# PIC32CK1025SG00064 device description
Architecture: CORTEX-M33; Family: PIC32CK; Series: PIC32CKSG00
Registers are 32-bit, read-write, reset 0x0 unless marked. A register's access mark holds for its fields unless they carry their own. Offsets are from the block's base; [hi:lo] are bit positions; lines under a group give offsets from that group; {n}, {i} and the like mark numbered series; 'fields as' and 'values as' point back to an identical list; <NAME> marks a mode.

## USBHS — USB High Speed
Instances: USBHS 0x46000000
Modes: ENDPOINTX when USBHS.INDEX.SELEP=1 (Endpont 1-15 are selected. INDEX.SELEP value needs to be greater than 0); ENDPOINT0 when USBHS.INDEX.SELEP=0 (Endpont 0 is selected)
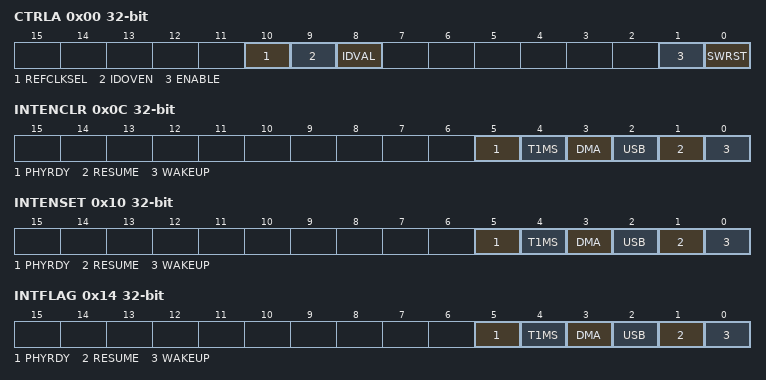
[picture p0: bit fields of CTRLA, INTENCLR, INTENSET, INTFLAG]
0x00 CTRLA — USBHS Control Register A. (All bits except ENABLE and SWRST are Enable protected)
  [10] REFCLKSEL — Select USB PLL Reference Clock Speed
  [9] IDOVEN — ID Source Select
  [8] IDVAL — Override Valud of ID
  [1] ENABLE — USBHS Enable
  [0] SWRST — USBHS Software Reset
0x04 CTRLB — USBHS Control Register B
  [19:0] BLANK — Blank the wakeup monitoring for a specific real time
    0=No blank delay; 0xFFFFF=BLANKMAX (Maximum blank delay)
0x08 CTRLC — USBHS Control Register C
  [4] T1MSEN — REFCLK and SUSPENDM override
0x0C INTENCLR (atomic clear) — USBHS Interrupt Enable Clear Register
  [5] PHYRDY — Clear PHYRDY Interrupt Enable
  [4] T1MS — Clear T1MS Interrupt Enable
  [3] DMA — Clear DMA Interrupt Enable
  [2] USB — Clear USBCORE General Interrupt Enable
  [1] RESUME — Clear Resume Interrupt Enable
  [0] WAKEUP — Clear USCORE Detaction Interrupt Enable
0x10 INTENSET (atomic set) — USBHS Interrupt Enable Clear Register
  [5] PHYRDY — PHYRDY Interrupt Enable
  [4] T1MS — T1MS Interrupt Enable
  [3] DMA — DMA Interrupt Enable
  [2] USB — USBCORE General Interrupt Enable
  [1] RESUME — Resume Interrupt Enable
  [0] WAKEUP — USCORE Detaction Interrupt Enable
0x14 INTFLAG (atomic clear) — USBHS Interrupt Flag Register
  [5] PHYRDY — PHY Ready Interrupt
  [4] T1MS — Timer 1ms Tick Interrupt
  [3] DMA — DMA Interrupt
  [2] USB — USBCORE General Interrupt
  [1] RESUME — Resume Interrupt
  [0] WAKEUP — USB Activity Detection Interrupt
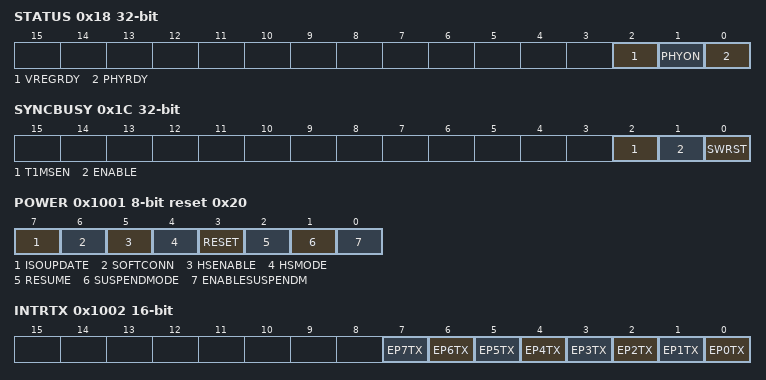
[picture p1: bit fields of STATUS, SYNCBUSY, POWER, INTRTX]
0x18 STATUS ro — USBHS Status Register
  [2] VREGRDY — USB Voltage Regulator Status
  [1] PHYON — Power On of PHY Complete
  [0] PHYRDY — PHY Is Ready for USBCORE Activity
0x1C SYNCBUSY ro — USBHS Syncbusy Register
  [2] T1MSEN — T1MS enable busy bit
  [1] ENABLE — Enable busy bit
  [0] SWRST — Software reset busy bit
0x1000 FADDR 8-bit — Function Address Register
  [6:0] FUNCADDR — Function address
0x1001 POWER 8-bit reset 0x20 — Used For Controlling Suspend And Resume Signaling And Some Basic Operation Of USBCORE
  [7] ISOUPDATE — when set by cpu the usbcore will wait for an sof token
  [6] SOFTCONN — if enabled the D+ D- lines are enabled when this bit is set by the cpu
  [5] HSENABLE — when set by cpu the usbcore will negotiate the high speed mode
  [4] HSMODE — when set this read only bit indicates high speed mode successfully negotiated during usb reset
  [3] RESET — this bit is set when reset signaling is present on the bus
  [2] RESUME — set by cpu to generate resume signaling when te device is in suspend
  [1] SUSPENDMODE — set by cpu to enter suspend mode
  [0] ENABLESUSPENDM — set by the cpu to enable suspendm output
0x1002 INTRTX 16-bit ro (atomic clear) — Read Only Register Which Indicates Which Interrupts Are Currently Active For EP0 And TX EP1-15
  [n] EP{n}TX (n=0..7) — Interrupts Active For TX{n} Endpoint
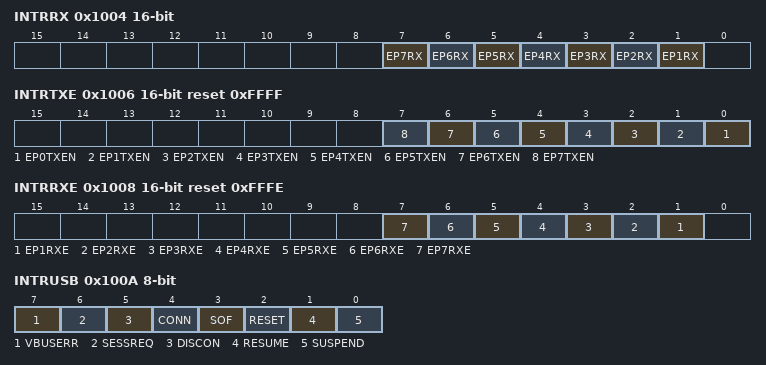
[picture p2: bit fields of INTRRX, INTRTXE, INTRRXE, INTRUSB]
0x1004 INTRRX 16-bit ro (atomic clear) — Read Only Register Which Indicates Which Interrupts Are Currently Active For RX EP1-15
  [n] EP{n}RX (n=1..7) — Interrupts Active For Which RX{n} Endpoint
0x1006 INTRTXE 16-bit reset 0xFFFF — Interrupt Enable Bits for INTRTX
  [n] EP{n}TXEN (n=0..7) — Interrupt Enabled for TX EP{n}
0x1008 INTRRXE 16-bit reset 0xFFFE — Interrupt Enable Bits for INTRRX
  [n] EP{n}RXE (n=1..7) — Interrupt Enabled for RX EP{n}
0x100A INTRUSB 8-bit ro (atomic clear) — Read Only Register Which Indicates Which USB Interrupts Are Currently Active.
  [7] VBUSERR — Set When VBus Drops Below The VBus Valid Threshold During A Session.
  [6] SESSREQ — Set When Session Request Signaling Has Been Detected.
  [5] DISCON — Set In Host Mode When A Device Disconnect Is Detected.Set In Peripheral Mode When A Session Ends
  [4] CONN — Set When A Device Connection Is Detected
  [3] SOF — Set When A New Frame Starts
  [2] RESET — Set In Peripheral Mode when Reset Is Detected On The Bus. In HostMode When Babble Is Detected
  [1] RESUME — Set When Resume Signal Is Detected On The Bus
  [0] SUSPEND — Set When Suspend Signal Is Detected On The Bus
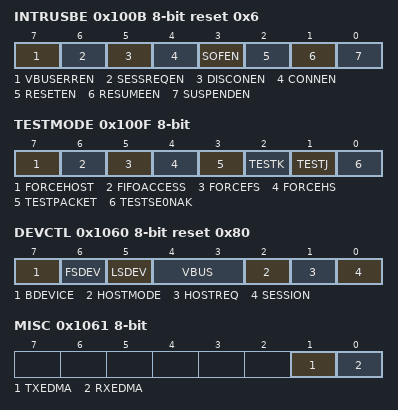
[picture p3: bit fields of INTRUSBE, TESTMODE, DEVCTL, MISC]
0x100B INTRUSBE 8-bit reset 0x6 — Interrupt Enable Bits for USB Interrupts
  [7] VBUSERREN — VBus Error Interrupt Enable
  [6] SESSREQEN — SESSREQ Interrupt Enable
  [5] DISCONEN — DISCONN Interrupt Enable
  [4] CONNEN — CONN Interrupt Enable
  [3] SOFEN — SOF Interrupt Enable
  [2] RESETEN — RESET/BABBLE Interrupt Enable
  [1] RESUMEEN — RESUME Interrupt Enable
  [0] SUSPENDEN — SUSEPND Interrupt Enable
0x100C FRAME 16-bit ro — Holds The Last Received Frame Number
  [10:0] FRMNUM — Frame Number
0x100E INDEX 8-bit — Index Is A 4-Bit Register That Determines Which Endpoint Control/Status Registers Are Accessed
  [3:0] SELEP — The Selected Endpoint
    {v}=EP{v} (Endpoint {v} Select) (v=0..8)
0x100F TESTMODE 8-bit — Not Used In Normal Operation. Configuration To Put the USBCORE Into One Of The Four Test Modes For HighSpeed Operation
  [7] FORCEHOST — The CPU Sets This Bit To Instruct The Core To Enter Host Mode When The Session Bit Is Set
  [6] FIFOACCESS — The CPU Sets This Bit To Transfer The Packet In The Endpoint 0 TX FIFO To The Endpoint 0 Rx FIFO. It Is Cleared Automatically.
  [5] FORCEFS — Depending On Bit 7 Force Controller Into FS Speed Mode
  [4] FORCEHS — Depending On Bit 7 Force Controller Into High Speed Mode
  [3] TESTPACKET — Set To Enter The Test_Packet mode
  [2] TESTK — Set To Enter The Test_K mode
  [1] TESTJ — Set To Enter The Test_J mode
  [0] TESTSE0NAK — Set To Enter The Test_SE0_NAK mode
{0x1020+4i} FIFOX[{i}] (i=0..7) — Address Range Provides 16 Addresses For CPU Access To The FIFO's For Each Endpoint
  [31:0] FIFOADDR — Writing To These Addresses Loads Data Into The TXFIFO For The Corresponding Endpoint
0x1060 DEVCTL 8-bit reset 0x80 — Selects Whether The Core Is Operating In Peripheral Or Host Mode
  [7] BDEVICE — indicates whether the core is operating as a 'A' device or 'B' device
  [6] FSDEV — host mode only: this bit is set when a full or high speed device has been detected being connected to the port
  [5] LSDEV — host mode only: this bit is set when a low speed device has been detected being connected to the port
  [4:3] VBUS — encoded value for the VBus level
    0=BSESSEND (Below SessionEnd); 1=ASESSEND (Above SessionEnd, below AValid); 2=AAVALID (Above AValid, below VBus Valid); 3=AVBUSVALID (Above VBusValid)
  [2] HOSTMODE — this read-only bit is set when the USBCORE is acting as a host
  [1] HOSTREQ — when set, the USBCORE will initiate the host negotiation when suspend mode is entered.
  [0] SESSION — when operating as an 'A' device, this bit is set or cleared by CPU to state or end a session. when operating as a 'B' device, this bit is set/cleared by the USBCORE when a session starts/ends
0x1061 MISC 8-bit — RX/TX Early DMA Enable Bits
  [1] TXEDMA — DMA_REQ signal for all IN endpoints will be deasserted based on this bit selection
    0=MAXP (Dma_req signal for all in endpoints will be de-asserted when maxp bytes have been written to an endpoint. this is late mode.); 1=MAXP_8 (Dma_req signal for all in endpoints will be de-asserted when maxp-8 bytes have been written to an endpoint. this is early mode.)
  [0] RXEDMA — DMA_REQ signal for all OUT endpoints will be deasserted based on this bit selection
    0=MAXP (Dma_req signal for all out endpoints will be de-asserted when maxp bytes have been written to an endpoint. this is late mode.); 1=MAXP_8 (Dma_req signal for all out endpoints will be de-asserted when maxp-8 bytes have been written to an endpoint. this is early mode.)
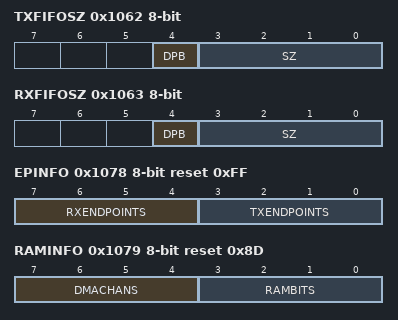
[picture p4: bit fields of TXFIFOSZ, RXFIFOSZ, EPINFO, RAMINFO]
0x1062 TXFIFOSZ 8-bit — Controls The Size Of The Selected TX Endpoint FIFO
  [4] DPB — double packet buffering supported or not
  [3:0] SZ — maximum packet size to be allowed
    0=8BYTES; 1=16BYTES; 2=32BYTES; 3=64BYTES; 4=128BYTES; 5=256BYTES; 6=512BYTES; 7=1024BYTES; 8=2048BYTES; 9=4096BYTES
0x1063 RXFIFOSZ 8-bit — Controls The Size Of The Selected RX Endpoint FIFO
  [4] DPB — double packet buffering enabled or not
  [3:0] SZ — maximum packet size to be allowed
    values as TXFIFOSZ.SZ
0x1064 TXFIFOADD 16-bit — Controls The Start Address Of the Selected TX Endpoint FIFO
  [12:0] ADDR — start address of the endpoint FIFO
0x1066 RXFIFOADD 16-bit — Controls The Start Address Of the Selected RX Endpoint FIFO
  [12:0] ADDR — start address of the endpoint FIFO
0x1078 EPINFO 8-bit ro reset 0xFF — Allows Read-Back Of The Number Of TX And RX Endpoints
  [7:4] RXENDPOINTS — number of rx endpoints
  [3:0] TXENDPOINTS — number of tx endpoints
0x1079 RAMINFO 8-bit ro reset 0x8D — Details About Width Of RAM and DMA Channels
  [7:4] DMACHANS — number of dma channels implemented in the design
  [3:0] RAMBITS — width of the ram address bus
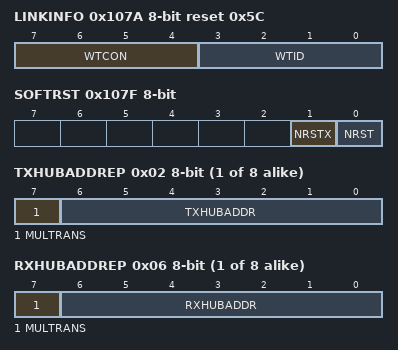
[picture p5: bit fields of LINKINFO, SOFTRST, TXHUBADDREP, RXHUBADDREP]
0x107A LINKINFO 8-bit reset 0x5C — Allows Some Delays To Be Specified
  [7:4] WTCON — sets the wait to be applied to allow for the user's connect/disconnect filter in units of 533.3ns
  [3:0] WTID — sets the delay to be applied from idpullup being asserted to iddig being considered valid in units of 4.369ms
0x107B VPLEN 8-bit reset 0x3C — Sets The Duration Of The VBus Pulsing Charge
  [7:0] VPLEN — duration of VBus pulsing charge in units of 546.1us
0x107C HSEOF1 8-bit reset 0x80 — Sets The Minimum Time Gap That Is To Be Allowed Between The Start Of The Last Transaction And The EOF For HS Transactions
  [7:0] HSEOF1 — sets for high-speed transactions the time before eof to stop beginning new transactions, in units of 133.3ns. (the default setting corresponds to 17.07us.)
0x107D FSEOF1 8-bit reset 0x77 — Sets The Minimum Time Gap That Is To Be Allowed Between The Start Of The Last Transaction And The EOF For FS Transactions
  [7:0] FSEOF1 — sets for full-speed transactions the time before eof to stop beginning new transactions, in units of 533.3ns. (the default setting corresponds to 63.46us.)
0x107E LSEOF1 8-bit reset 0x72 — Sets The Minimum Time Gap That Is To Be Allowed Between The Start Of The Last Transaction And The EOF For LS Transactions
  [7:0] LSEOF1 — sets for low-speed transactions the time before eof to stop beginning new transactions, in units of 1.067us. (the default setting corresponds to 121.6us.)
0x107F SOFTRST 8-bit — Assert Low The Output Reset Signals NRSTO and NRSTXO
  [1] NRSTX — when a 1 is written to this bit, the output nrstxo will be asserted (low) within a minimum delay of 7 cycles of the clk input. the output nrstxo will be asynchronously asserted and synchronously de-asserted with respect to xclk.
  [0] NRST — when a 1 is written to this bit, the output nrsto will be asserted (low) within a minimum delay of 7 cycles of the clk input. the output nrsto will be asynchronously asserted and synchronously de-asserted with respect to clk.
{0x1080+8i} TXFUNADDR[{i}] (i=0..7) group
  0x00 TXFUNCADDREP 8-bit — Relevant In Host Mode Only. Address Of The Target Function.
    [6:0] TXFUNCADDR — address of the target function
  0x02 TXHUBADDREP 8-bit — Relevant In Host Mode Only. HUB Address
    [7] MULTRANS — hub has multiple or single translator
    [6:0] TXHUBADDR — hub address
  0x03 TXHUBPORT 8-bit — Relevant In Host Mode Only. HUB Address
    [6:0] HUBPORT
  0x04 RXFUNCADDREP 8-bit — Relevant In Host Mode Only. Address Of The Target Function.
    [6:0] RXFUNCADDR — address of the target function
  0x06 RXHUBADDREP 8-bit — Relevant In Host Mode Only. HUB Address
    [7] MULTRANS — hub has multiple or single translator
    [6:0] RXHUBADDR — hub address
  0x07 RXHUBPORT 8-bit — Relevant In Host Mode Only. HUB Address
    [6:0] HUBPORT
0x1200 DMAINTR — DMA Interrupt Status for Each Channel
  [7:0] DMAINTR — DMA Interrupt for each channel
{0x1204+0x10*i} DMACNT[{i}] (i=0..7) group
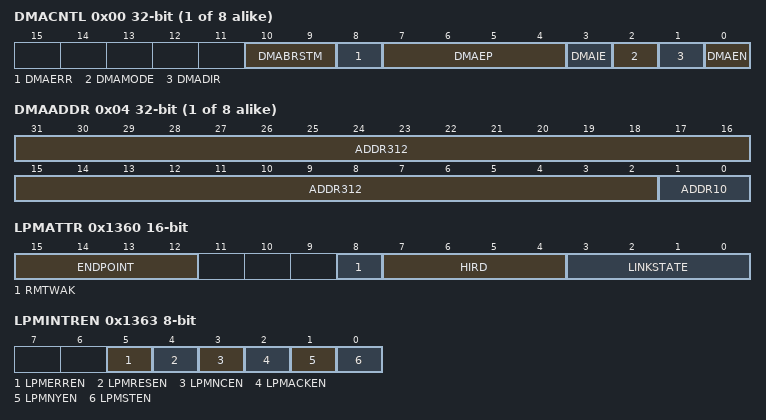
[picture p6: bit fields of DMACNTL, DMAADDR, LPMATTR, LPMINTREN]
  0x00 DMACNTL — DMA Transfer Control For Each Channel
    [10:9] DMABRSTM — burst mode
      {v}=BM{v} (Burst Mode {v}) (v=0..3)
    [8] DMAERR — bus error bit
    [7:4] DMAEP — endpoint number this channel is assigned to
    [3] DMAIE — interrupt enable
    [2] DMAMODE — transfer mode
      0=MODE0 (Mode 0 Transfer); 1=MODE1 (Mode1 Transfer)
    [1] DMADIR — transfer direction
      0=WRITE (DMA Write (RX Endpoint)); 1=READ (DMA Read (TX Endpoint))
    [0] DMAEN — dma transfer enable
  0x04 DMAADDR — Memory Address Of The Corresponding DMA Channel
    [31:2] ADDR312 — upper 30 bits of address
    [1:0] ADDR10 — Lower 2 bits of DMA memory address
  0x08 DMACOUNT — Current DMA Count Of The Transfer
    [31:0] DMACOUNT — current dma count of the transfer
{0x1304+4i} RQPKTCOUNT[{i}] (i=0..6) — Host Mode Only: Used To Specify Number Of Packets That Are To Be Transaferred In A Block Transfer
  [15:0] RQPKTCOUNT — sets the number of packets of size maxp that are to be transferred in a block transfer. only used in host mode when autoreq is set. has no effect in peripheral mode or when autoreq is not set.
0x1340 RXDPKTBUFDIS 16-bit — Indicates Which Of The RX Endpoints Have Disabled Double Packet Buffer Functionality
  [15:1] EPxRXDIS — each bit indicates which of the Rx endpoint have disabled double buffer functionality
0x1342 TXDPKTBUFDIS 16-bit — Indicates Which Of The TX Endpoints Have Disabled Double Packet Buffer Functionality
  [15:1] EPxTXDIS — each bit indicates which of the Tx endpoint have disabled double buffer functionality
0x1344 CTUCH 16-bit reset 0x4074 — Chirp Timeout. Number Of XCLK Cycles Before The Timeout
  [15:0] CTUCH — this number when multiplied by 4 represents the number of xclk cycles before the timeout occurs
0x1346 CTHHSRTN 16-bit reset 0x32 — Sets The Delay From The End Of High-Speed Resume Signaling (Acting As A Host) To Enable The UTM Normal Operating Mode
  [15:0] CTHHSRTN — the delay from the end of high speed resume signaling to enabling utm normal operating mode.
0x1348 CTHSBT 16-bit — This Register Represents The Value To Be Added To The Minimum High Speed Timeout Period Of 736 Bit Times.
  [3:0] HSTMEOUTADD — this register represents the value to be added to the mimumum high speed timeout period of 736 bit times
0x1360 LPMATTR 16-bit — Defines The Attributes Of An LPM Transaction And Sleep Cycle.
  [15:12] ENDPOINT — this is the endpnt that in the token packet of the lpm transaction.
  [8] RMTWAK — this bit is the remote wakeup enable bit.
  [7:4] HIRD — this is the host initiated resume duration.
  [3:0] LINKSTATE — this value is provided by the host to the peripheral to indicate what state the peripheral must transition to after the receipt and acceptance of a lpm transaction.
    1=SLEEPSTATE (Sleep State (L1))
0x1362 LPMCNTRL 8-bit (modes: HOST when USBHS.DEVCTL.HOSTMODE=1; PERIPHERAL when USBHS.DEVCTL.HOSTMODE=0) — LPM Control Register
  [1] LPMRES <HOST> — this bit is used by software to initiate a resume from the l1 state
  [0] LPMXMT <HOST> — software should set this bit to transmit an lpm transaction.
  [4] LPMNAK <PERIPHERAL> — this bit is used to place all end points in a state such that the response to all transactions other then an lpm transaction will be a nak.
  [3:2] LPMEN <PERIPHERAL> — this register is used to enable lpm in the musbmhdrc.
    0=LPMTRANS (Core supports LPM extended transactions); 1=EXTNTRANS (LPM is not supported but extended transactions are supported.); 2=NOTSUPPORTED1 (LPM and extended transactions are not supported); 3=NOTSUPPORTED2 (LPM and extended transactions are not supported)
  [1] LPMRES <PERIPHERAL> — this bit is used by software to initiate resume (remote wakeup).
  [0] LPMXMT <PERIPHERAL> — this bit is set by software to instruct the core to transition to the l1 state upon the receipt of the next lpm transaction.
0x1363 LPMINTREN 8-bit — LPM Interrupts Enable Register
  [5] LPMERREN — LPMERR interrupt
  [4] LPMRESEN — LPMRES interrupt
  [3] LPMNCEN — LPMNC interrupt
  [2] LPMACKEN — LPMACK interrupt
  [1] LPMNYEN — LPMMNY interrupt
  [0] LPMSTEN — LPMMST interrupt
0x1364 LPMINTR 8-bit (modes: HOST when USBHS.DEVCTL.HOSTMODE=1; PERIPHERAL when USBHS.DEVCTL.HOSTMODE=0) — Status Of The LPM Power State
  [5] LPMERR <HOST> — this bit is set if a response to the lpm transaction is received with a bit stuff error or a pid error
  [4] LPMRES <HOST> — this bit is set when the core has been resumed for any reason.
  [3] LPMNC <HOST> — this bit is set when an lpm transaction has been transmitted and has failed to complete.
  [2] LPMACK <HOST> — this bit is set when an lpm transaction is transmitted and the device responds with an ack.
  [1] LPMNY <HOST> — this bit is set when an lpm transaction is transmitted and the device responds with a nyet.
  [0] LPMST <HOST> — this bit is set when an lpm transaction is transmitted and the device responds with a stall.
  [5] LPMERR <PERIPHERAL> — this bit is set if an lpm transaction is received that has a linkstate field that is not supported
  [4] LPMRES <PERIPHERAL> — this bit is set if the core has been resumed for any reason.
  [3] LPMNC <PERIPHERAL> — this bit is set when an lpm transaction is received and the core responds with a nyet due to data pending in the rx fifos.
  [2] LPMACK <PERIPHERAL> — this bit is set when an lpm transaction is received and the core responds with an ack.
  [1] LPMNY <PERIPHERAL> — this bit is set when an lpm transaction is received and the core responds with a nyet
  [0] LPMST <PERIPHERAL> — this bit is set when an lpm transaction is received and the core responds with a stall.
0x1365 LPMFADDR 8-bit — Function Address In LPM Payload
  [6:0] FUNCADDR — function address that will be placed in the LPM payload
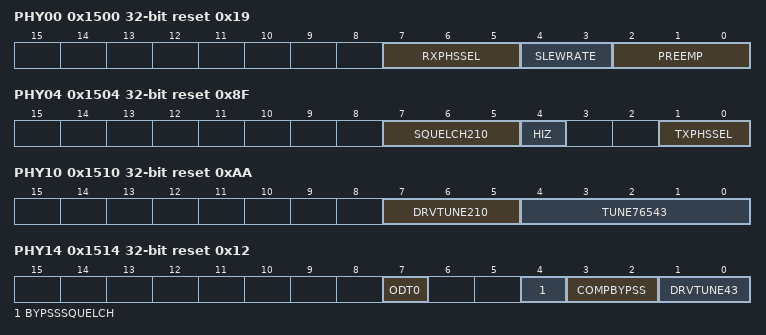
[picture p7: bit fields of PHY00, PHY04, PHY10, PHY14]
0x1500 PHY00 reset 0x19 — USBHPHY Control Register.
  [7:5] RXPHSSEL — RX clock phase select
    0=EARLIEST (Earliest phase); 7=LATEST (Latest phase)
  [4:3] SLEWRATE — adjust FS/LS slew rate
    0=HIGH (Highest slew rate); 1=MIDDLE0 (Middle slew rate); 2=MIDDLE1 (Middle slew rate); 3=SMALLEST (Smallest slew rate)
  [2:0] PREEMP — enables pre-emphasis
    0=SOFEOP (Enable pre-emphasis during SOF and EOP); 1=CHIRP (Enable pre-emphasis during chirp); 2=NONCHIRP (Enable pre-emphasis in non-chirp state); 3=ALWAYS (Always enable pre-emphasis)
0x1504 PHY04 reset 0x8F — USBHPHY Control Register.
  [7:5] SQUELCH210 — Lower 3 bits of RX squelch trigger point configuration
  [4] HIZ — Set D+/D- to a high impedence state
  [1:0] TXPHSSEL — set the Tx clock phase select
0x1508 PHY08 reset 0x7 — USBHPHY Control Register.
  [0] SQUELCH3 — MSB of Squelch configuration
0x150C PHY0C reset 0xE0 — USBHPHY Control Register.
  [11:5] TUNE210 — Lower 3 bits for HS amplitude tuning
0x1510 PHY10 reset 0xAA — USBHPHY Control Register.
  [7:5] DRVTUNE210 — Lower 3 bits for HS/FS/LS driver strength tuning
  [4:0] TUNE76543 — Upper 5 bits for HS amplitude tuning
0x1514 PHY14 reset 0x12 — USBHPHY Control Register.
  [7] ODT0 — On die termination compensation voltage reference
  [4] BYPSSSQUELCH — Bypass squelch trigger point configure in chirp mode
  [3:2] COMPBYPSS — Auto compensation bypass
  [1:0] DRVTUNE43 — Upper 2 bits for HS/FS/LS driver strength tuning
0x1518 PHY18 reset 0x8 — USBHPHY Control Register.
  [1:0] ODT21 — Upper 3 bits for on die termination compensation voltage reference
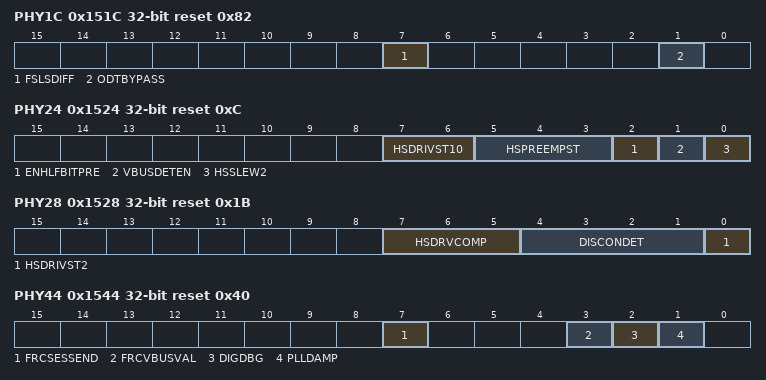
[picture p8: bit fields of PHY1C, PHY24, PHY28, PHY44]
0x151C PHY1C reset 0x82 — USBHPHY Control Register.
  [7] FSLSDIFF — Turn off FS/LS differential receiver in suspend mode
  [1] ODTBYPASS — ODT auto-refresh bypass
0x1520 PHY20 reset 0x80 — USBHPHY Control Register.
  [7:6] HSSLEW10 — Lower 2 bits for HS slew adjust rate
0x1524 PHY24 reset 0xC — USBHPHY Control Register.
  [7:6] HSDRIVST10 — HS transmit drive strength
  [5:3] HSPREEMPST — HS transmit pre emphasis strength
  [2] ENHLFBITPRE — Enable half-bit pre-emphasis for HS transmit
  [1] VBUSDETEN — VBUS Detection Switch 0 - Closed, 1 - Open
  [0] HSSLEW2 — MSB of HS slew rate adjust
0x1528 PHY28 reset 0x1B — USBHPHY Control Register.
  [7:5] HSDRVCOMP — HS drive current compensation voltage reference
  [4:1] DISCONDET — HOST disconnects detection trigger point
  [0] HSDRIVST2 — MSB of HS transmit driver strength
0x1544 PHY44 reset 0x40 — USBHPHY Control Register.
  [7] FRCSESSEND — force session end
  [3] FRCVBUSVAL — Force output vbus_valid
  [2] DIGDBG — Digital debug interface
  [1] PLLDAMP — PLL damping factor
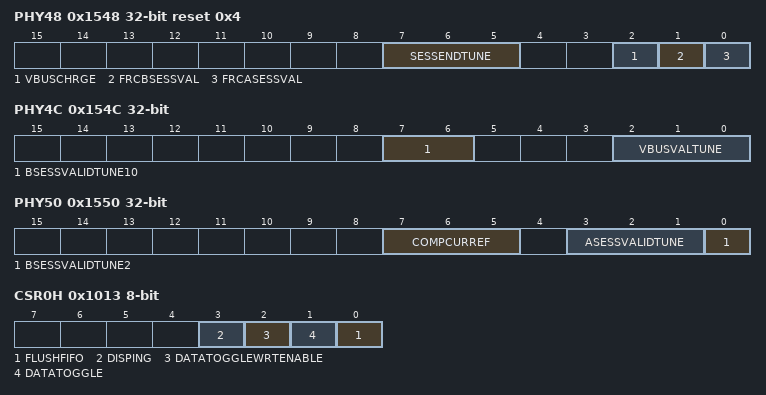
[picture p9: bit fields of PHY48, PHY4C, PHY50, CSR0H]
0x1548 PHY48 reset 0x4 — USBHPHY Control Register.
  [7:5] SESSENDTUNE — Session end reference tuning
  [2] VBUSCHRGE — VBus charging/discharging bypass
  [1] FRCBSESSVAL — force B_sessionvalid
  [0] FRCASESSVAL — force A_sessionvalid
0x154C PHY4C — USBHPHY Control Register.
  [7:6] BSESSVALIDTUNE10 — Lower 2 B_sessionvalid reference tune
  [2:0] VBUSVALTUNE — VBus_valid reference tuning
0x1550 PHY50 — USBHPHY Control Register.
  [7:5] COMPCURREF — Compensation current tuning reference
  [3:1] ASESSVALIDTUNE — A_sessionvalid reference tune
  [0] BSESSVALIDTUNE2 — MSB of B_sessionvalid reference tune
0x1012 CSR0L <ENDPOINT0> 8-bit (modes: HOST_EP0 when USBHS.DEVCTL.HOSTMODE=1; PERIPHERAL_EP0 when USBHS.DEVCTL.HOSTMODE=0) — ENDPOINT0 Control And Status Bits for TX Endpoint 0
  [1] TXPKTRDY — The CPU Sets This Bit After Loading A Data Packet Into The FIFO.
  [0] RXPKTRDY — This Bit Is Set When A Data Packet Has Been Received
  [7] NAKTIMEOUT <HOST_EP0> — This Bit Will Be Set When Endpoint 0 Is Halted Following The Receipt Of NAK Responses For Longer Than The Time Set By The NAKLimit0 register.
  [6] STATUSPKT <HOST_EP0> — The CPU Sets This Bit At The Same Time As The TxPktRdy Or ReqPkt Bit Is Set, To Perform A Status Stage Transaction
  [5] REQPKT <HOST_EP0> — The CPU Sets This Bit To Request An IN Transaction
  [4] ERROR <HOST_EP0> — This Bit Will Be Set When Three Attempts Have Been Made To Perform A Transaction With No Response From The Peripheral
  [3] SETUPPKT <HOST_EP0> — The CPU Sets This Bit, At The Same Time As The TxPktRdy Bit Is Set, To Send A SETUP Token Instead Of An OUT Token For The Transaction
  [2] RXSTALL <HOST_EP0> — This Bit Is Set When A Stall Handshake Is Received.
  [7] SERVICEDSETUPEND <PERIPHERAL_EP0> — The CPU Writes A 1 To This Bit To Clear The SetupEnd Bit. It Is Cleared Automatically.
  [6] SERVICEDRXPKTRDY <PERIPHERAL_EP0> — The CPU Writes A 1 To This Bit To Clear The RxPktRdy Bit. It Is Cleared Automatically
  [5] SENDSTALL <PERIPHERAL_EP0> — The CPU Writes A 1 To This Bit To Terminate The Current Transaction
  [4] SETUPEND <PERIPHERAL_EP0> — This Bit Will Be Set When A Control Transaction Ends Before The DataEnd Bit Has Been Set
  [3] DATAEND <PERIPHERAL_EP0> — The CPU Sets This Bit 1. When Setting TxPktRdy For The Last Data Packet 2. When Clearing RxPktRdy After Unloading The Last Data Packet.3. When Setting TxPktRdy For A Zero Length Data Packet.
  [2] SENTSTALL <PERIPHERAL_EP0> — This Bit Is Set When A Stall Handshake Is Transmitted.
0x1013 CSR0H <ENDPOINT0> 8-bit (modes: HOST_EP0 when USBHS.DEVCTL.HOSTMODE=1; PERIPHERAL_EP0 when USBHS.DEVCTL.HOSTMODE=0) — ENDPOINT0 Additional Control And Status Bits For TX Endpoint 0
  [0] FLUSHFIFO — Flush The Next Packet To Be Transmitted/Read
  [3] DISPING <HOST_EP0> — The CPU Writes A 1 To This Bit To Instruct The Core Not To Issue PING Tokens In Data And Status Phases Of A High-Speed Control Transfer
  [2] DATATOGGLEWRTENABLE <HOST_EP0> — The CPU Writes A 1 To This Bit To Enable The Current State Of The Endpoint 0 Data Toggle To Be Written
  [1] DATATOGGLE <HOST_EP0> — When Read, This Bit Indicates The Current State Of The Endpoint 0 Data Toggle
0x1018 COUNT0 <ENDPOINT0> 8-bit ro — ENDPOINT0 Number Of Received Bytes In Endpoint 0 FIFO
  [6:0] EP0RXCOUNT — Number Of Received Data Bytes In Endpoint 0 FIFO
0x101A TYPE0 <ENDPOINT0> 8-bit — ENDPOINT0 Host Mode Only: Operating Speed Of The Targeted Device
  [7:6] SPEED — Operating Speed Of The Target Device
    1=HIGH (Device In High Speed); 2=FULL (Device In Full Speed); 3=LOW (Device In Low Speed)
0x101B NAKLIMIT0 <ENDPOINT0> 8-bit — ENDPOINT0 Host Mode Only: Sets The NAK Response Timeout On Endpoint 0.
  [4:0] EP0NAKLIMIT — Number Of Frames/Microframes After Which Endpoint 0 Should Timeout
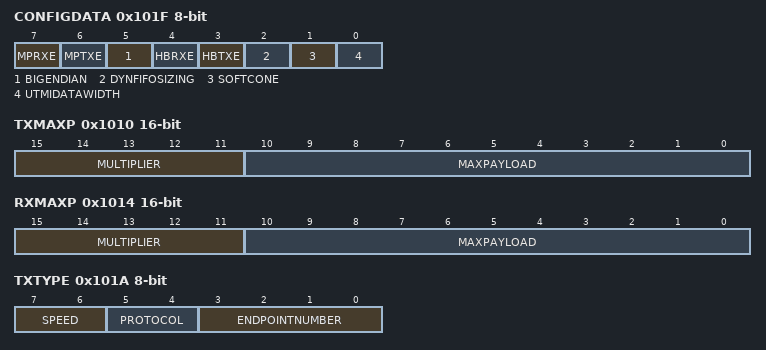
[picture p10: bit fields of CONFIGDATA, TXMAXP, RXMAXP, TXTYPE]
0x101F CONFIGDATA <ENDPOINT0> 8-bit ro — ENDPOINT0 Returns Information About The Selected Core Configuration. Only Applicable when INDEX Regsiter Is 0. That Is Endpoint0 Is Selected.
  [7] MPRXE — Automatic Splitting Of Bulk Amalgamation Is Selected
  [6] MPTXE — Automatic Splitting Of Bulk Packets Is Selected
  [5] BIGENDIAN — Indicates Little Endian Ordering
  [4] HBRXE — Indicates High Bandwidth RX ISO Endpoint Support Selected
  [3] HBTXE — Indicates High Bandwidth TX ISO Endpoint Support Selected
  [2] DYNFIFOSIZING — Dynamic FIFO Sizing Is Selected Or Not
  [1] SOFTCONE — Indicates Soft Connect Or Disconnect
  [0] UTMIDATAWIDTH — Indicates Selected UTMI+ DataWidth. Always 0 Indicates 8 Bits
0x1010 TXMAXP <ENDPOINTX> 16-bit — ENDPOINTX Maximum Amount Of Data That Can Be Transferred Through The Selected TX Endpoint In A Single Operation
  [15:11] MULTIPLIER — Multiplier Value (m-1)
  [10:0] MAXPAYLOAD — Maximum Payload/Transactions
0x1012 TXCSRL <ENDPOINTX> 8-bit (modes: HOST_EPX when USBHS.DEVCTL.HOSTMODE=1; PERIPHERAL_EPX when USBHS.DEVCTL.HOSTMODE=0) — ENDPOINTX Control And Status Bits for TX Endpoints 1-15
  [6] CLRDATATOG — The CPU Writes A 1 To This Bit To Reset The Endpoint Data Toggle To 0.
  [3] FLUSHFIFO — The CPU Writes A 1 To This Bit To Flush The Latest Packet From The Endpoint TX FIFO
  [1] FIFONOTEMPTY — The USB Sets This Bit When There Is At Least 1 Packet In The TX FIFO.
  [0] TXPKTRDY — The CPU Sets This Bit After Loading A Data Packet Into The FIFO.
  [7] NAKTIMEOUT <HOST_EPX> — This Bit Will Be Set When Endpoint 0 Is Halted Following The Receipt Of NAK Responses For Longer Than The Time Set By The NAKLimit0 register.
  [5] RXSTALL <HOST_EPX> — This Bit Is Set When A Stall Handshake Is Received.
  [4] SETUPPKT <HOST_EPX> — The CPU Sets This Bit, At The Same Time As The TxPktRdy Bit Is Set, To Send A SETUP Token Instead Of An OUT Token For The Transaction
  [2] ERROR <HOST_EPX> — This Bit Will Be Set When Three Attempts Have Been Made To Perform A Transaction With No Response From The Peripheral
  [7] INCOMPTX <PERIPHERAL_EPX> — When The Endpoint Is Being Used For High-Bandwidth Isochronous, This Bit Is Set To Indicate Where A Large Packet Has Been Split Into 2 Or 3 Packets For Transmission But Insufficient IN Tokens Have Been Received To Send All The Parts.
  [5] SENTSTALL <PERIPHERAL_EPX> — This Bit Is Set When A Stall Handshake Is Transmitted.
  [4] SENDSTALL <PERIPHERAL_EPX> — The CPU Writes A 1 To This Bit To Issue A Stall Handshake To An In Token
  [2] UNDERRUN <PERIPHERAL_EPX> — The USB Sets This Bit If An In Token Is Received When TxPktRdy Is Not Set.
0x1013 TXCSRH <ENDPOINTX> 8-bit (modes: HOST_EPX when USBHS.DEVCTL.HOSTMODE=1; PERIPHERAL_EPX when USBHS.DEVCTL.HOSTMODE=0) — ENDPOINTX Additional Control And Status Bits For TX Endpoints 1-15
  [5] MODE — The CPU Sets This Bit To Enable The Endpoint Direction As TX
  [7] AUTOSET <HOST_EPX> — If The CPU Sets This Bit, TxPktRdy Will Be Automatically Set When Data Of The Maximum P
  [4] DMAREQENAB <HOST_EPX> — The CPU Sets This Bit To Enable The DMA Request For The RX Endpoint
  [3] FRCDATATOG <HOST_EPX> — The CPU Sets This Bit To Force The Endpoint Data Toggle To Switch And The Data Packe
  [2] DMAREQMODE <HOST_EPX> — The CPU Sets This Bit To Select DMA Request Mode
  [1] DATATOGGLEWRENABLE <HOST_EPX> — The CPU Writes A 1 To This Bit To Enable The Current State Of The Endpoint 0 Data Toggle To Be Written
  [0] DATATOGGLE <HOST_EPX> — When Read, This Bit Indicates The Current State Of The Endpoint
  [7] AUTOSET <PERIPHERAL_EPX> — If The CPU Sets This Bit, TxPktRdy Will Be Automatically Set When Data Of The Maximum Packet Size Is Loaded Into The TX FIFO.
  [6] ISO <PERIPHERAL_EPX> — The CPU Sets This Bit To Enable The TX Endpoint For Isochronous Transfers
  [4] DMAREQENAB <PERIPHERAL_EPX> — The CPU Sets This Bit To Enable The DMA Request For The TX Endpoint
  [3] FRCDATATOG <PERIPHERAL_EPX> — The CPU Sets This Bit To Force The Endpoint Data Toggle To Switch And The Data Packet To Be Cleared From The FIFO.
  [2] DMAREQMODE <PERIPHERAL_EPX> — The CPU Sets This Bit To Select DMA Request Mode 1 And Clears It To Select DMA Request Mode 0.
0x1014 RXMAXP <ENDPOINTX> 16-bit — ENDPOINTX Maximum Amount Of Data That Can Be Transferred Through The Selected RX Endpoint In A Single Operation
  fields as TXMAXP<ENDPOINTX>
0x1016 RXCSRL <ENDPOINTX> 8-bit (modes: HOST_EPX when USBHS.DEVCTL.HOSTMODE=1; PERIPHERAL_EPX when USBHS.DEVCTL.HOSTMODE=0) — ENDPOINTX Control And Status Bits for RX Endpoint 0 Or Endpoint 1-15
  [7] CLRDATATOG — The CPU Writes A 1 To This Bit To Reset The Endpoint Data Toggle To 0.
  [4] FLUSHFIFO — The CPU Writes A 1 To This Bit To Flush The Next Packet To Be Read From The Endpoint Rx FIFO
  [0] RXPKTRDY — This Bit Is Set When A Data Packet Has Been Received.
  [6] RXSTALL <HOST_EPX> — When A STALL Handshake Is Received, This Bit Is Set And An Interrupt Is Generated.
  [5] REQPKT <HOST_EPX> — The CPU Writes A 1 To This Bit To Request An IN Transaction.
  [3] NAKTIMEOUT <HOST_EPX> — This Bit Is Set When RxPktRdy Is Set If The Data Packet Has A CRC Or Bit-stuff Error.
  [2] ERROR <HOST_EPX> — The USB Sets This Bit When 3 Attempts Have Been Made To Receive A Packet And No Data Packet Has Been Received.
  [1] FIFOFULL <HOST_EPX> — This Bit Is Set When No More Packets Can Be Loaded
  [6] SENTSTALL <PERIPHERAL_EPX> — This Bit Is Set When A STALL Handshake Is Transmitted.
  [5] SENDSTALL <PERIPHERAL_EPX> — The CPU Writes A 1 To This Bit To Issue A STALL Handshake.
  [3] DATAERROR <PERIPHERAL_EPX> — This Bit Is Set When RxPktRdy Is Set If The Data Packet Has A CRC Or Bit-stuff Error.
  [2] OVERRUN <PERIPHERAL_EPX> — This Bit Is Set If An OUT Packet Cannot Be Loaded Into The Rx FIFO.
  [1] FIFOFULL <PERIPHERAL_EPX> — This Bit Is Set When No More Packets Can Be Loaded Into The Rx FIFO.
0x1017 RXCSRH <ENDPOINTX> 8-bit (modes: HOST_EPX when USBHS.DEVCTL.HOSTMODE=1; PERIPHERAL_EPX when USBHS.DEVCTL.HOSTMODE=0) — ENDPOINTX Additional Control And Status Bits for RX Endpoint 0 Or Endpoint 1-15
  [5] DMAREQENAB — The CPU Sets This Bit To Enable The DMA Request For The RX Endpoint
  [3] DMAREQMODE — The CPU Sets This Bit To Select DMA Request Mode
  [7] AUTOCLEAR <HOST_EPX> — If The CPU Sets This Bit, TxPktRdy Will Be Automatically Cleared When A Packet Of RxMaxP Bytes Has Been Unloaded From The RX FIFO
  [6] AUTOREQ <HOST_EPX> — If The CPU Sets This Bit, The ReqPkt Bit Will Be Automatically Set When The RxPktRdy Bit Is Cleared.
  [4] PIDERROR <HOST_EPX> — Indicates A PID Error In The Received Packet
  [2] DATATOGGLEWRTENABLE <HOST_EPX> — The CPU Writes A 1 To This Bit To Enable The Current State Of The Endpoint 0 Data Toggle To Be Written
  [1] DATATOGGLE <HOST_EPX> — When Read, This Bit Indicates The Current State Of The Endpoint
  [0] INCOMPRX <HOST_EPX> — This Bit Is Set In A High-Bandwidth Isochronous/Interrupt Transfer If The Packet In The Rx FIFO Is Incomplete
  [7] AUTOCLEAR <PERIPHERAL_EPX> — If The CPU Sets This Bit Then The RxPktRdy Bit Will Be Automatically Cleared Whean A Packet Of RxMaxP Bytes Has Benn Unloaded Froim The Rx FIFO
  [6] ISO <PERIPHERAL_EPX> — The CPU Sets This Bit To Enable the RX Endpoint For Isochronous Transfers
  [4] DISNYET <PERIPHERAL_EPX> — The CPU Sets This Bit To Disable The Sending Of NYET Handshakes
  [0] INCOMPRX <PERIPHERAL_EPX> — This Bit Is Set In A High-Bandwidth Isochronous/Interrupt Transfer If The Packet In The Rx FIFO Is Incomplete Because Parts Of The Data Were Not Received.
0x1018 RXCOUNT <ENDPOINTX> 16-bit ro — ENDPOINTX Number Of Data Bytes In The Packet Currently In Line To Be Read From The RX FIFO.
  [13:0] ENDPOINTRXCOUNT — Number Of Data Bytes In The Packet Currently In Line To Be Read From The RX FIFO.
0x101A TXTYPE <ENDPOINTX> 8-bit — ENDPOINTX Host Mode Only: Should Be Written With The Endpoint Number To Be Targeted By The Endpoint
  [7:6] SPEED — operating speed of the target device when the core is configured with the multipoint option: 00: unused (note: if selected, the target will be assumed to be using the same connection speed as the core.) 01: high 10: full 11: low
    values as TYPE0<ENDPOINT0>.SPEED
  [5:4] PROTOCOL — the cpu should set this to select the required protocol for the tx endpoint 00: control 01: isochronous 10: bulk 11: interrupt
    0=CONTROL; 1=ISOCHRONOUS; 2=BULK; 3=INTERRUPT
  [3:0] ENDPOINTNUMBER — the cpu should set this value to the endpoint number contained in the tx endpoint descriptor
0x101B TXINTERVAL <ENDPOINTX> 8-bit — ENDPOINTX Host Mode Only: Defines The Polling Interval For The Currently Selected TX Endpoint.
  [7:0] TXPOLLINGINTERVAL — polling interval
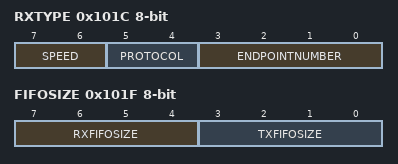
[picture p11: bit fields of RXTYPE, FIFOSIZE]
0x101C RXTYPE <ENDPOINTX> 8-bit — ENDPOINTX Host Mode Only: Should Be Written With The Endpoint Number To Be Targeted By The Endpoint
  [7:6] SPEED — operating speed of the target device when the core is configured with the multipoint option: 00: unused (note: if selected, the target will be assumed to be using the same connection speed as the core.) 01: high 10: full 11: low
    1=HIGH; 2=FULL; 3=LOW
  [5:4] PROTOCOL — the cpu should set this to select the required protocol for the rx endpoint 00: control 01: isochronous 10: bulk 11: interrupt
    0=CONTROL; 1=ISOCHRONOUS; 2=BULK; 3=INTERRUPT
  [3:0] ENDPOINTNUMBER — the cpu should set this value to the endpoint number contained in the rx endpoint descriptor returned to the musbmhdrc during device enumeration.
0x101D RXINTERVAL <ENDPOINTX> 8-bit — ENDPOINTX Host Mode Only: Defines The Polling Interval For The Currently Selected RX Endpoint.
  [7:0] RXPOLLINGINTERVAL — polling interval
0x101F FIFOSIZE <ENDPOINTX> 8-bit ro — ENDPOINTX Read Only Register That Returns The Sizes Of The FIFO's Associated With The Selected Additional TX/RX Endpoints. INDEX Regsiter should be set 1-15
  [7:4] RXFIFOSIZE, [3:0] TXFIFOSIZE
